# STM32F107 register map
File version: 1.2
CPU: CM3 r1p1, little endian, no MPU, no FPU, 4 interrupt priority bits
Registers are 32-bit, read-write, reset 0x0 unless marked. A register's access mark holds for its fields unless they carry their own. Offsets are from the block's base; [hi:lo] are bit positions; lines under a group give offsets from that group; {n}, {i} and the like mark numbered series.

## ADC1 — Analog to digital converter
Base 0x40012400
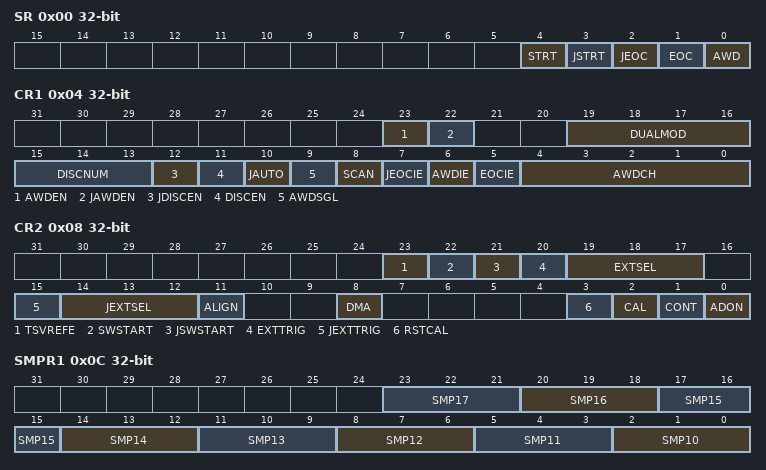
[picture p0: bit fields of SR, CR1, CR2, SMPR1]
0x00 SR — status register
  [4] STRT — Regular channel start flag
  [3] JSTRT — Injected channel start flag
  [2] JEOC — Injected channel end of conversion
  [1] EOC — Regular channel end of conversion
  [0] AWD — Analog watchdog flag
0x04 CR1 — control register 1
  [23] AWDEN — Analog watchdog enable on regular channels
  [22] JAWDEN — Analog watchdog enable on injected channels
  [19:16] DUALMOD — Dual mode selection
  [15:13] DISCNUM — Discontinuous mode channel count
  [12] JDISCEN — Discontinuous mode on injected channels
  [11] DISCEN — Discontinuous mode on regular channels
  [10] JAUTO — Automatic injected group conversion
  [9] AWDSGL — Enable the watchdog on a single channel in scan mode
  [8] SCAN — Scan mode
  [7] JEOCIE — Interrupt enable for injected channels
  [6] AWDIE — Analog watchdog interrupt enable
  [5] EOCIE — Interrupt enable for EOC
  [4:0] AWDCH — Analog watchdog channel select bits
0x08 CR2 — control register 2
  [23] TSVREFE — Temperature sensor and VREFINT enable
  [22] SWSTART — Start conversion of regular channels
  [21] JSWSTART — Start conversion of injected channels
  [20] EXTTRIG — External trigger conversion mode for regular channels
  [19:17] EXTSEL — External event select for regular group
  [15] JEXTTRIG — External trigger conversion mode for injected channels
  [14:12] JEXTSEL — External event select for injected group
  [11] ALIGN — Data alignment
  [8] DMA — Direct memory access mode
  [3] RSTCAL — Reset calibration
  [2] CAL — A/D calibration
  [1] CONT — Continuous conversion
  [0] ADON — A/D converter ON / OFF
0x0C SMPR1 — sample time register 1
  [3n-28:3n-30] SMP{n} (n=10..17) — Channel {n} sampling time selection
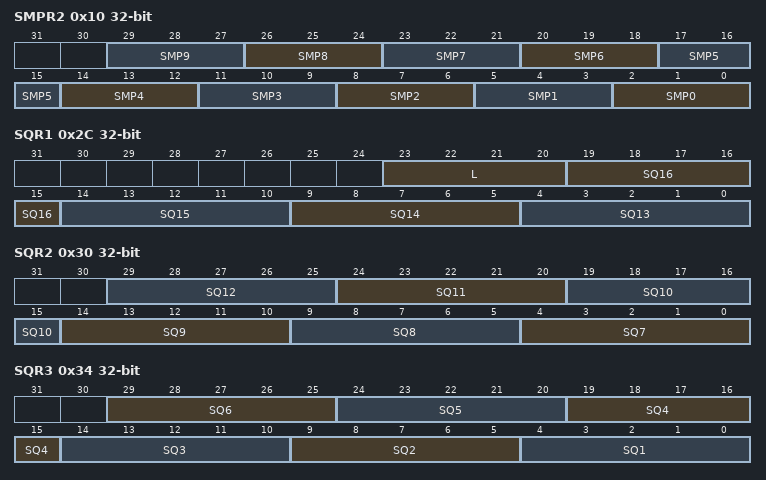
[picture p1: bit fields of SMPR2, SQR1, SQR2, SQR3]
0x10 SMPR2 — sample time register 2
  [3n+2:3n] SMP{n} (n=0..9) — Channel {n} sampling time selection
{0x10+4i} JOFR{i} (i=1..4) — injected channel data offset register x
  [11:0] JOFFSET{i} — Data offset for injected channel x
0x24 HTR reset 0xFFF — watchdog higher threshold register
  [11:0] HT — Analog watchdog higher threshold
0x28 LTR — watchdog lower threshold register
  [11:0] LT — Analog watchdog lower threshold
0x2C SQR1 — regular sequence register 1
  [23:20] L — Regular channel sequence length
  [5n-61:5n-65] SQ{n} (n=13..16) — {n}th conversion in regular sequence
0x30 SQR2 — regular sequence register 2
  [5n-31:5n-35] SQ{n} (n=7..12) — {n}th conversion in regular sequence
0x34 SQR3 — regular sequence register 3
  [29:25] SQ6 — 6th conversion in regular sequence
  [24:20] SQ5 — 5th conversion in regular sequence
  [19:15] SQ4 — 4th conversion in regular sequence
  [14:10] SQ3 — 3rd conversion in regular sequence
  [9:5] SQ2 — 2nd conversion in regular sequence
  [4:0] SQ1 — 1st conversion in regular sequence
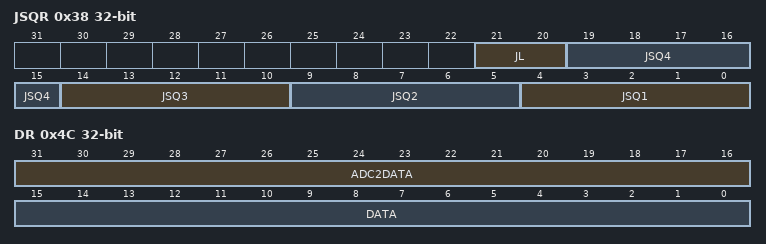
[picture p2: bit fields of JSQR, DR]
0x38 JSQR — injected sequence register
  [21:20] JL — Injected sequence length
  [19:15] JSQ4 — 4th conversion in injected sequence
  [14:10] JSQ3 — 3rd conversion in injected sequence
  [9:5] JSQ2 — 2nd conversion in injected sequence
  [4:0] JSQ1 — 1st conversion in injected sequence
{0x38+4i} JDR{i} ro (i=1..4) — injected data register x
  [15:0] JDATA — Injected data
0x4C DR ro — regular data register
  [31:16] ADC2DATA
  [15:0] DATA — Regular data

## ADC2 — Analog to digital converter
Base 0x40012800
Registers as ADC1; these are added or differ:
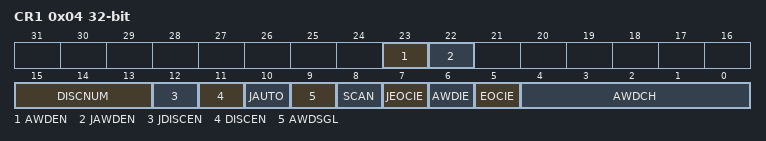
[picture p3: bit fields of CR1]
0x04 CR1 — control register 1
  [23] AWDEN — Analog watchdog enable on regular channels
  [22] JAWDEN — Analog watchdog enable on injected channels
  [15:13] DISCNUM — Discontinuous mode channel count
  [12] JDISCEN — Discontinuous mode on injected channels
  [11] DISCEN — Discontinuous mode on regular channels
  [10] JAUTO — Automatic injected group conversion
  [9] AWDSGL — Enable the watchdog on a single channel in scan mode
  [8] SCAN — Scan mode
  [7] JEOCIE — Interrupt enable for injected channels
  [6] AWDIE — Analog watchdog interrupt enable
  [5] EOCIE — Interrupt enable for EOC
  [4:0] AWDCH — Analog watchdog channel select bits
0x4C DR ro — regular data register
  [15:0] DATA — Regular data

## ADC3 — Analog to digital converter
Base 0x40013C00
Registers as ADC1; these are added or differ:
0x0C SMPR1 — sample time register 1
  [31:0] SMPx_x — Sample time bits
0x10 SMPR2 — sample time register 2
  [31:0] SMPx_x — Sample time bits
0x4C DR ro — regular data register
  [15:0] DATA — Regular data
